# LargeDummyDevice register map
File version: 1.0
Registers are 32-bit, read-write, no defined reset value unless marked. A register's access mark holds for its fields unless they carry their own. Offsets are from the block's base; [hi:lo] are bit positions.

## PERIPHERAL_84
Base 0x40053000
0x04 REG_1 — Register 1
  [30:28] FIELD_19, [29:25] FIELD_20, [23] FIELD_8, [23:22] FIELD_6, [24:22] FIELD_13, [23:20] FIELD_7, [22:19] FIELD_4, [19:17] FIELD_5, [17:15] FIELD_15, [13] FIELD_2, [16:13] FIELD_16, [15:13] FIELD_18, [11] FIELD_9, [11:9] FIELD_14, [8:6] FIELD_10, [9:5] FIELD_1, [8:5] FIELD_3, [2] FIELD_11, [2:1] FIELD_12, [1:0] FIELD_17
0x08 REG_2 — Register 2
  [34:31] FIELD_4, [31] FIELD_14, [35:31] FIELD_25, [30] FIELD_24, [32:29] FIELD_3, [27:26] FIELD_18, [25] FIELD_11, [27:24] FIELD_9, [24:23] FIELD_20, [22:18] FIELD_8, [17] FIELD_13, [17] FIELD_17, [19:17] FIELD_26, [19:16] FIELD_10, [20:16] FIELD_16, [17:15] FIELD_7, [15:14] FIELD_21, [14] FIELD_22, [16:14] FIELD_23, [17:13] FIELD_1, [17:13] FIELD_15, [15:12] FIELD_5, [11:8] FIELD_19, [9:7] FIELD_12, [7:6] FIELD_2, [2:1] FIELD_6
0x0C REG_3 — Register 3
  [30:28] FIELD_10, [27] FIELD_5, [30:27] FIELD_6, [27] FIELD_8, [30:27] FIELD_11, [28:26] FIELD_3, [30:26] FIELD_7, [17] FIELD_4, [19:17] FIELD_13, [17] FIELD_16, [19:17] FIELD_17, [16:13] FIELD_14, [11] FIELD_15, [13:9] FIELD_2, [9:8] FIELD_9, [10:8] FIELD_12, [5:2] FIELD_1, [2] FIELD_19, [3:0] FIELD_18
0x10 REG_4 — Register 4
  [31] FIELD_8, [35:31] FIELD_9, [33:31] FIELD_20, [31:30] FIELD_15, [31:29] FIELD_21, [28] FIELD_3, [28] FIELD_25, [24] FIELD_11, [24] FIELD_14, [27:23] FIELD_7, [19] FIELD_23, [19:18] FIELD_1, [20:17] FIELD_13, [19:16] FIELD_5, [17:14] FIELD_2, [14:12] FIELD_12, [11] FIELD_4, [10] FIELD_24, [10:9] FIELD_16, [10:7] FIELD_19, [10:6] FIELD_6, [9:5] FIELD_22, [8:4] FIELD_10, [5:3] FIELD_17, [6:3] FIELD_18
0x14 REG_5 — Register 5
  [31] FIELD_12, [35:31] FIELD_15, [32:30] FIELD_22, [32:29] FIELD_9, [31:28] FIELD_19, [30:27] FIELD_6, [27:26] FIELD_16, [29:25] FIELD_4, [29:25] FIELD_8, [26:25] FIELD_10, [23:21] FIELD_13, [21:19] FIELD_11, [23:19] FIELD_21, [20:16] FIELD_5, [16:14] FIELD_2, [12] FIELD_17, [13:11] FIELD_1, [15:11] FIELD_3, [9] FIELD_20, [6:5] FIELD_7, [3] FIELD_14, [3:0] FIELD_18, [3:0] FIELD_23
0x18 REG_6 — Register 6
  [33:31] FIELD_21, [35:31] FIELD_24, [30] FIELD_10, [30] FIELD_31, [32:29] FIELD_6, [31:27] FIELD_8, [27] FIELD_30, [30:26] FIELD_17, [27:25] FIELD_9, [26:25] FIELD_18, [25] FIELD_27, [23] FIELD_14, [25:23] FIELD_26, [26:22] FIELD_2, [25:22] FIELD_29, [21] FIELD_1, [21] FIELD_4, [21:18] FIELD_7, [21:17] FIELD_5, [20:17] FIELD_23, [17:13] FIELD_32, [13:12] FIELD_19, [11] FIELD_25, [12:8] FIELD_13, [9:5] FIELD_11, [5:4] FIELD_3, [6:4] FIELD_12, [4] FIELD_15, [4] FIELD_16, [6:3] FIELD_20, [2:1] FIELD_22, [2:0] FIELD_28
0x1C REG_7 — Register 7
  [34:30] FIELD_15, [28:26] FIELD_3, [28:25] FIELD_7, [26:25] FIELD_8, [29:25] FIELD_9, [28:24] FIELD_12, [23:19] FIELD_2, [22:19] FIELD_5, [21:18] FIELD_1, [17:14] FIELD_11, [13:11] FIELD_6, [10:7] FIELD_10, [10:7] FIELD_14, [4] FIELD_13, [5:1] FIELD_4
0x20 REG_8 — Register 8
  [33:30] FIELD_13, [29:28] FIELD_1, [31:27] FIELD_10, [20] FIELD_12, [22:18] FIELD_8, [16:14] FIELD_3, [15:12] FIELD_11, [11] FIELD_6, [12:10] FIELD_7, [11:7] FIELD_9, [5] FIELD_5, [8:4] FIELD_2, [1] FIELD_4
0x24 REG_9 — Register 9
  [33:31] FIELD_7, [31:30] FIELD_11, [33:29] FIELD_3, [30:29] FIELD_13, [31:28] FIELD_14, [29:26] FIELD_2, [28:24] FIELD_4, [26:22] FIELD_1, [23:20] FIELD_5, [20] FIELD_15, [23:19] FIELD_12, [19:18] FIELD_18, [20:17] FIELD_17, [11:10] FIELD_6, [10:9] FIELD_8, [6] FIELD_9, [3] FIELD_16, [4:2] FIELD_10
0x28 REG_10 — Register 10
  [35:31] FIELD_12, [31] FIELD_14, [28:27] FIELD_10, [24:22] FIELD_13, [23:20] FIELD_2, [21:20] FIELD_11, [18:16] FIELD_9, [17:15] FIELD_3, [12:11] FIELD_5, [12:10] FIELD_4, [10:6] FIELD_8, [7:5] FIELD_15, [7:4] FIELD_1, [4:3] FIELD_6, [7:3] FIELD_7
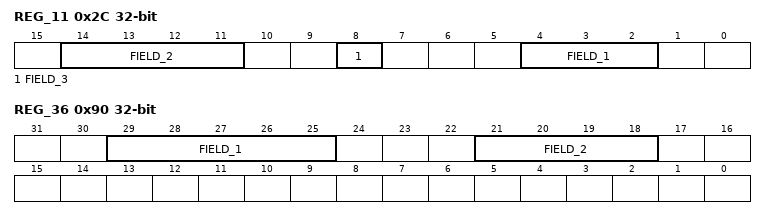
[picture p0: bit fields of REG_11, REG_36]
0x2C REG_11 — Register 11
  [14:11] FIELD_2, [8] FIELD_3, [4:2] FIELD_1
0x30 REG_12 — Register 12
  [31] FIELD_16, [29] FIELD_24, [28:26] FIELD_7, [29:26] FIELD_15, [25:24] FIELD_13, [24:23] FIELD_31, [22] FIELD_2, [24:22] FIELD_14, [23:22] FIELD_20, [22:21] FIELD_10, [20] FIELD_4, [24:20] FIELD_8, [21:20] FIELD_21, [18] FIELD_1, [19:18] FIELD_3, [18] FIELD_29, [18:17] FIELD_23, [19:17] FIELD_27, [18:16] FIELD_11, [18:16] FIELD_22, [17:16] FIELD_28, [19:15] FIELD_25, [15:11] FIELD_9, [11:10] FIELD_12, [9] FIELD_18, [8] FIELD_6, [9:8] FIELD_19, [5] FIELD_30, [4] FIELD_5, [3:2] FIELD_17, [2] FIELD_26
0x34 REG_13 — Register 13
  [31] FIELD_27, [32:30] FIELD_9, [32:30] FIELD_11, [30:28] FIELD_8, [28] FIELD_14, [31:28] FIELD_17, [29:25] FIELD_19, [27:23] FIELD_22, [22] FIELD_20, [26:22] FIELD_23, [25:22] FIELD_29, [21] FIELD_1, [24:21] FIELD_18, [24:20] FIELD_4, [23:19] FIELD_31, [20:18] FIELD_25, [17] FIELD_26, [16] FIELD_12, [15] FIELD_28, [13] FIELD_3, [15:13] FIELD_5, [13:12] FIELD_6, [13:12] FIELD_15, [12] FIELD_30, [11:10] FIELD_2, [13:10] FIELD_10, [10:9] FIELD_24, [7:6] FIELD_21, [7:5] FIELD_16, [5:1] FIELD_13, [2:0] FIELD_7
0x38 REG_14 — Register 14
  [33:30] FIELD_8, [22:18] FIELD_5, [19:17] FIELD_2, [16:13] FIELD_1, [16:13] FIELD_3, [12:10] FIELD_4, [7:5] FIELD_7, [7:3] FIELD_6
0x3C REG_15 — Register 15
  [31:29] FIELD_16, [31:28] FIELD_6, [31:27] FIELD_10, [28:27] FIELD_27, [28:25] FIELD_7, [28:24] FIELD_8, [25:23] FIELD_25, [23] FIELD_30, [23:19] FIELD_19, [17] FIELD_3, [20:17] FIELD_13, [16:14] FIELD_1, [17:14] FIELD_12, [17:14] FIELD_15, [16:13] FIELD_21, [16:13] FIELD_23, [14:12] FIELD_18, [10] FIELD_24, [11:10] FIELD_29, [13:9] FIELD_2, [12:8] FIELD_20, [12:8] FIELD_22, [9:6] FIELD_28, [7:6] FIELD_31, [5] FIELD_26, [5:4] FIELD_17, [6:3] FIELD_4, [3] FIELD_9, [7:3] FIELD_14, [2:1] FIELD_5, [0] FIELD_11
0x40 REG_16 — Register 16
  [33:30] FIELD_19, [28:27] FIELD_28, [29:26] FIELD_5, [28:26] FIELD_6, [26:24] FIELD_27, [27:23] FIELD_24, [26:22] FIELD_2, [22:21] FIELD_4, [24:21] FIELD_17, [19] FIELD_7, [21:19] FIELD_23, [22:18] FIELD_13, [17] FIELD_14, [15] FIELD_8, [17:15] FIELD_15, [13] FIELD_21, [17:13] FIELD_22, [13:12] FIELD_16, [12:11] FIELD_10, [14:11] FIELD_25, [10] FIELD_26, [8] FIELD_9, [10:8] FIELD_20, [6:5] FIELD_1, [5:4] FIELD_11, [7:3] FIELD_18, [2] FIELD_3, [2:1] FIELD_12
0x44 REG_17 — Register 17
  [12:11] FIELD_2, [12:10] FIELD_1
0x48 REG_18 — Register 18
  [34:30] FIELD_3, [30] FIELD_9, [30:28] FIELD_10, [26:25] FIELD_4, [19:18] FIELD_7, [18] FIELD_8, [19:16] FIELD_6, [19:16] FIELD_11, [16:14] FIELD_5, [13:12] FIELD_2, [10] FIELD_1
0x4C REG_19 — Register 19
  [30] FIELD_8, [31:28] FIELD_9, [28:26] FIELD_6, [24:23] FIELD_10, [24:22] FIELD_5, [25:21] FIELD_4, [22:21] FIELD_12, [21:20] FIELD_3, [19:16] FIELD_7, [15:14] FIELD_2, [13:10] FIELD_1, [4] FIELD_11
0x50 REG_20 — Register 20
  [28:26] FIELD_1, [23:20] FIELD_4, [23:19] FIELD_3, [22:18] FIELD_6, [8:5] FIELD_5, [1] FIELD_2
0x54 REG_21 — Register 21
  [33:31] FIELD_5, [32:30] FIELD_6, [30:29] FIELD_12, [30:29] FIELD_19, [29:28] FIELD_15, [30:27] FIELD_13, [31:27] FIELD_25, [25] FIELD_24, [28:24] FIELD_7, [25:23] FIELD_3, [23] FIELD_32, [26:22] FIELD_31, [20] FIELD_10, [21:20] FIELD_14, [20:18] FIELD_1, [17] FIELD_11, [21:17] FIELD_27, [20:16] FIELD_17, [17:15] FIELD_4, [18:15] FIELD_22, [16:13] FIELD_23, [17:13] FIELD_26, [10:9] FIELD_28, [10:8] FIELD_2, [9:6] FIELD_20, [5] FIELD_21, [4] FIELD_16, [5:4] FIELD_29, [1] FIELD_8, [2:1] FIELD_9, [1:0] FIELD_18, [1:0] FIELD_30
0x58 REG_22 — Register 22
  [32:31] FIELD_10, [30] FIELD_23, [29] FIELD_12, [31:27] FIELD_24, [27:25] FIELD_6, [29:25] FIELD_16, [25:24] FIELD_4, [26:22] FIELD_8, [21:20] FIELD_26, [22:18] FIELD_19, [19:17] FIELD_18, [18:15] FIELD_3, [19:15] FIELD_9, [16:15] FIELD_25, [16:14] FIELD_15, [12:11] FIELD_14, [11:10] FIELD_5, [9:8] FIELD_1, [12:8] FIELD_7, [6] FIELD_2, [6] FIELD_11, [6:4] FIELD_20, [3] FIELD_13, [6:3] FIELD_21, [2:0] FIELD_17, [3:0] FIELD_22
0x5C REG_23 — Register 23
  [21:18] FIELD_1
0x60 REG_24 — Register 24
  [33:31] FIELD_28, [34:30] FIELD_6, [33:30] FIELD_14, [32:30] FIELD_21, [32:28] FIELD_10, [29:28] FIELD_19, [29:27] FIELD_18, [27:26] FIELD_27, [25:23] FIELD_3, [25:23] FIELD_4, [25:23] FIELD_9, [25:22] FIELD_26, [22:19] FIELD_22, [20:18] FIELD_12, [22:18] FIELD_24, [20:16] FIELD_1, [12] FIELD_13, [13:9] FIELD_16, [10:8] FIELD_8, [7] FIELD_23, [9:6] FIELD_11, [8:6] FIELD_20, [6:3] FIELD_7, [7:3] FIELD_15, [5:1] FIELD_17, [1] FIELD_25, [3:0] FIELD_2, [2:0] FIELD_5
0x64 REG_25 — Register 25
  [31:28] FIELD_13, [26] FIELD_11, [28:26] FIELD_18, [25:21] FIELD_8, [22:19] FIELD_14, [20:18] FIELD_15, [16] FIELD_9, [15] FIELD_4, [15] FIELD_7, [18:15] FIELD_17, [17:13] FIELD_12, [15:11] FIELD_1, [13:11] FIELD_10, [11:7] FIELD_2, [7:6] FIELD_6, [8:5] FIELD_3, [6:2] FIELD_5, [2:0] FIELD_16
0x68 REG_26 — Register 26
  [31] FIELD_7, [34:30] FIELD_14, [30:29] FIELD_8, [32:28] FIELD_13, [29:27] FIELD_5, [29:26] FIELD_10, [26:25] FIELD_18, [24] FIELD_9, [27:23] FIELD_12, [23:21] FIELD_1, [24:21] FIELD_11, [21:17] FIELD_6, [18:16] FIELD_17, [19:15] FIELD_3, [10:9] FIELD_16, [7:6] FIELD_2, [5:3] FIELD_15, [2:1] FIELD_4
0x6C REG_27 — Register 27
  [32:30] FIELD_3, [32:28] FIELD_12, [28] FIELD_25, [29:27] FIELD_6, [27] FIELD_10, [26] FIELD_19, [27:25] FIELD_7, [24] FIELD_2, [27:23] FIELD_4, [24:23] FIELD_9, [23] FIELD_14, [25:21] FIELD_5, [21:20] FIELD_18, [20:19] FIELD_20, [20:19] FIELD_22, [18] FIELD_23, [16:14] FIELD_17, [14:12] FIELD_13, [12:10] FIELD_8, [12:8] FIELD_15, [10:7] FIELD_11, [8:5] FIELD_16, [6:3] FIELD_21, [6:2] FIELD_1, [3:2] FIELD_24, [3:0] FIELD_26
0x70 REG_28 — Register 28
  [30] FIELD_1, [31:28] FIELD_2, [25:24] FIELD_14, [27:23] FIELD_3, [27:23] FIELD_12, [26:22] FIELD_6, [25:22] FIELD_13, [21:18] FIELD_7, [14:12] FIELD_11, [12:10] FIELD_8, [9:7] FIELD_4, [2] FIELD_9, [3:2] FIELD_10, [3:0] FIELD_5
0x74 REG_29 — Register 29
  [34:31] FIELD_2, [31:30] FIELD_14, [34:30] FIELD_18, [29:27] FIELD_15, [29:26] FIELD_22, [25:24] FIELD_4, [24] FIELD_28, [25:23] FIELD_17, [22] FIELD_24, [21] FIELD_10, [21:20] FIELD_12, [21:18] FIELD_7, [21:17] FIELD_11, [18:17] FIELD_26, [14:13] FIELD_8, [12:11] FIELD_9, [11:10] FIELD_6, [14:10] FIELD_20, [14:10] FIELD_23, [10:9] FIELD_3, [11:9] FIELD_21, [11:9] FIELD_27, [11:8] FIELD_13, [11:7] FIELD_25, [6] FIELD_30, [5] FIELD_1, [7:4] FIELD_16, [6:3] FIELD_19, [2:1] FIELD_29, [4:0] FIELD_5
0x78 REG_30 — Register 30
  [31] FIELD_8, [26:24] FIELD_6, [25:23] FIELD_2, [23:22] FIELD_20, [21:20] FIELD_9, [24:20] FIELD_15, [23:20] FIELD_18, [21:19] FIELD_11, [20:19] FIELD_17, [21:18] FIELD_14, [16:13] FIELD_19, [12] FIELD_7, [15:12] FIELD_16, [11] FIELD_5, [9] FIELD_10, [11:8] FIELD_4, [9:5] FIELD_12, [6:5] FIELD_13, [6:4] FIELD_3, [1] FIELD_1
0x7C REG_31 — Register 31
  [31] FIELD_11, [33:31] FIELD_13, [28] FIELD_22, [29:26] FIELD_5, [27:25] FIELD_21, [26:24] FIELD_17, [27:24] FIELD_18, [23] FIELD_7, [24:22] FIELD_29, [25:21] FIELD_23, [23:19] FIELD_1, [20:19] FIELD_3, [21:19] FIELD_8, [19] FIELD_30, [22:18] FIELD_2, [21:18] FIELD_6, [20:16] FIELD_14, [17:16] FIELD_24, [17:15] FIELD_9, [16:15] FIELD_20, [18:15] FIELD_25, [17:14] FIELD_4, [17:14] FIELD_27, [14:10] FIELD_16, [12:8] FIELD_28, [8:7] FIELD_15, [6] FIELD_12, [7:6] FIELD_19, [7:3] FIELD_26, [3:1] FIELD_10
0x80 REG_32 — Register 32
  [31:28] FIELD_3, [32:28] FIELD_5, [26:24] FIELD_1, [24:22] FIELD_7, [24:21] FIELD_6, [21:18] FIELD_4, [17] FIELD_8, [1] FIELD_2
0x84 REG_33 — Register 33
  [33:29] FIELD_12, [25:23] FIELD_8, [27:23] FIELD_13, [18:17] FIELD_1, [16] FIELD_11, [15:13] FIELD_16, [13:10] FIELD_3, [12:10] FIELD_7, [10] FIELD_9, [12:8] FIELD_10, [9:5] FIELD_6, [5:3] FIELD_4, [6:2] FIELD_2, [4:2] FIELD_14, [3:0] FIELD_5, [1:0] FIELD_15
0x88 REG_34 — Register 34
  [32:31] FIELD_23, [31] FIELD_29, [31:29] FIELD_6, [30:29] FIELD_7, [31:29] FIELD_21, [31:28] FIELD_16, [27:26] FIELD_3, [27:26] FIELD_5, [27:26] FIELD_18, [29:25] FIELD_28, [24] FIELD_20, [24:21] FIELD_14, [21:20] FIELD_4, [19:16] FIELD_10, [18:16] FIELD_31, [16:15] FIELD_17, [15:14] FIELD_13, [17:13] FIELD_11, [10] FIELD_30, [10:9] FIELD_22, [12:8] FIELD_8, [8:7] FIELD_1, [9:7] FIELD_24, [7:6] FIELD_19, [7:5] FIELD_27, [8:4] FIELD_2, [6:4] FIELD_12, [4:3] FIELD_9, [7:3] FIELD_15, [5:1] FIELD_25, [2:1] FIELD_26
0x8C REG_35 — Register 35
  [32:31] FIELD_23, [31] FIELD_32, [28] FIELD_9, [29:28] FIELD_15, [27] FIELD_3, [29:27] FIELD_10, [28:25] FIELD_6, [29:25] FIELD_8, [28:25] FIELD_16, [29:25] FIELD_22, [26:23] FIELD_2, [24:23] FIELD_4, [26:23] FIELD_12, [25:22] FIELD_19, [20:17] FIELD_13, [20:16] FIELD_29, [16:15] FIELD_1, [17:15] FIELD_26, [17:15] FIELD_31, [16:14] FIELD_5, [16:12] FIELD_14, [12:11] FIELD_7, [14:11] FIELD_20, [10] FIELD_24, [12:9] FIELD_27, [9:8] FIELD_25, [6] FIELD_11, [6] FIELD_18, [8:5] FIELD_28, [6:4] FIELD_17, [8:4] FIELD_30, [3:0] FIELD_21
0x90 REG_36 — Register 36
  [29:25] FIELD_1, [21:18] FIELD_2
0x94 REG_37 — Register 37
  [31:30] FIELD_7, [33:30] FIELD_16, [33:29] FIELD_10, [29:25] FIELD_4, [26:25] FIELD_24, [26:22] FIELD_1, [24:22] FIELD_13, [22] FIELD_19, [21:20] FIELD_12, [22:18] FIELD_3, [21:18] FIELD_6, [18:17] FIELD_5, [21:17] FIELD_14, [18:16] FIELD_2, [18:15] FIELD_8, [16:15] FIELD_20, [13] FIELD_11, [14:12] FIELD_23, [13:11] FIELD_18, [13:11] FIELD_21, [14:10] FIELD_22, [6] FIELD_9, [2:1] FIELD_17, [4:0] FIELD_15
0x98 REG_38 — Register 38
  [31] FIELD_9, [31:30] FIELD_20, [31:29] FIELD_14, [25:24] FIELD_5, [26:22] FIELD_16, [22:19] FIELD_8, [21:18] FIELD_17, [18:16] FIELD_2, [19:16] FIELD_3, [19:15] FIELD_15, [16:12] FIELD_6, [14:12] FIELD_12, [12:10] FIELD_4, [12:10] FIELD_19, [12:9] FIELD_10, [6] FIELD_13, [6:5] FIELD_1, [8:4] FIELD_18, [3] FIELD_11, [0] FIELD_7
0x9C REG_39 — Register 39
  [35:31] FIELD_2, [29:27] FIELD_7, [22] FIELD_14, [23:21] FIELD_1, [19] FIELD_5, [20:18] FIELD_13, [17:16] FIELD_10, [18:14] FIELD_20, [13] FIELD_17, [13] FIELD_19, [11:9] FIELD_4, [8] FIELD_15, [9:7] FIELD_3, [7] FIELD_12, [7:6] FIELD_8, [9:5] FIELD_11, [6:5] FIELD_18, [4] FIELD_9, [8:4] FIELD_16, [5:3] FIELD_6
0xA0 REG_40 — Register 40
  [35:31] FIELD_3, [30] FIELD_15, [33:29] FIELD_9, [29] FIELD_26, [32:28] FIELD_17, [30:28] FIELD_25, [26] FIELD_27, [28:25] FIELD_18, [27:25] FIELD_20, [24] FIELD_12, [23] FIELD_11, [22:21] FIELD_16, [21] FIELD_21, [19] FIELD_4, [20:19] FIELD_8, [22:18] FIELD_7, [21:17] FIELD_23, [18:16] FIELD_13, [12] FIELD_10, [12] FIELD_14, [13:10] FIELD_2, [8:7] FIELD_24, [10:6] FIELD_1, [7:6] FIELD_6, [9:6] FIELD_22, [8:5] FIELD_19, [3] FIELD_5
0xA4 REG_41 — Register 41
  [35:31] FIELD_9, [32:30] FIELD_18, [32:29] FIELD_13, [26] FIELD_10, [26] FIELD_12, [25:22] FIELD_2, [23:20] FIELD_7, [22:20] FIELD_22, [24:20] FIELD_23, [19] FIELD_3, [20:17] FIELD_4, [20:17] FIELD_5, [18:17] FIELD_20, [20:16] FIELD_8, [18:15] FIELD_6, [14] FIELD_25, [17:13] FIELD_15, [16:13] FIELD_16, [10:8] FIELD_21, [8] FIELD_24, [5] FIELD_1, [4] FIELD_11, [3] FIELD_14, [4:3] FIELD_17, [1:0] FIELD_19
0xA8 REG_42 — Register 42
  [32:31] FIELD_20, [31:30] FIELD_10, [29:27] FIELD_14, [29:26] FIELD_1, [28:24] FIELD_13, [27:24] FIELD_17, [21:19] FIELD_19, [20:17] FIELD_9, [18:17] FIELD_21, [18:14] FIELD_4, [16:13] FIELD_8, [12:10] FIELD_16, [11:8] FIELD_5, [12:8] FIELD_7, [10:8] FIELD_12, [10:6] FIELD_2, [7:5] FIELD_6, [7:5] FIELD_18, [4:3] FIELD_15, [2:0] FIELD_3, [3:0] FIELD_11
0xAC REG_43 — Register 43
  [34:30] FIELD_4, [29:27] FIELD_21, [24:22] FIELD_5, [23:21] FIELD_11, [23:21] FIELD_16, [21:20] FIELD_2, [20:17] FIELD_10, [18:17] FIELD_12, [14] FIELD_13, [16:14] FIELD_17, [13] FIELD_3, [12] FIELD_15, [14:12] FIELD_18, [9] FIELD_8, [8] FIELD_6, [10:6] FIELD_9, [7:6] FIELD_14, [9:6] FIELD_19, [9:5] FIELD_20, [5:4] FIELD_1, [3] FIELD_7
0xB0 REG_44 — Register 44
  [34:31] FIELD_11, [32:28] FIELD_5, [28:27] FIELD_15, [28:26] FIELD_7, [24] FIELD_21, [24:23] FIELD_12, [22] FIELD_4, [24:20] FIELD_19, [21:18] FIELD_18, [20:16] FIELD_6, [18:16] FIELD_25, [16:14] FIELD_8, [15:14] FIELD_10, [17:13] FIELD_16, [12:11] FIELD_22, [12:11] FIELD_26, [11:8] FIELD_1, [9:7] FIELD_13, [11:7] FIELD_14, [10:7] FIELD_23, [5] FIELD_2, [6:5] FIELD_20, [7:4] FIELD_17, [5:2] FIELD_9, [5:1] FIELD_24, [1:0] FIELD_3
0xB4 REG_45 — Register 45
  [21:20] FIELD_3, [23:19] FIELD_1, [19:18] FIELD_5, [17:16] FIELD_2, [16] FIELD_4
0xB8 REG_46 — Register 46
  [29:28] FIELD_2, [26] FIELD_1, [25] FIELD_4, [29:25] FIELD_6, [24] FIELD_3, [24:20] FIELD_8, [8] FIELD_5, [4] FIELD_7
